# R7FA6T1 register map
Vendor: Renesas; Series: RA6; File version: 1.2
CPU: CM4 r0p1, little endian, MPU, FPU, VTOR, 4 interrupt priority bits
Registers are 8-bit, read-write, reset 0x0 unless marked. A register's access mark holds for its fields unless they carry their own. Offsets are from the block's base; [hi:lo] are bit positions; 'fields as' and 'values as' point back to an identical list.

## MSTP — Module Stop Control B,C,D
Base 0x40047000
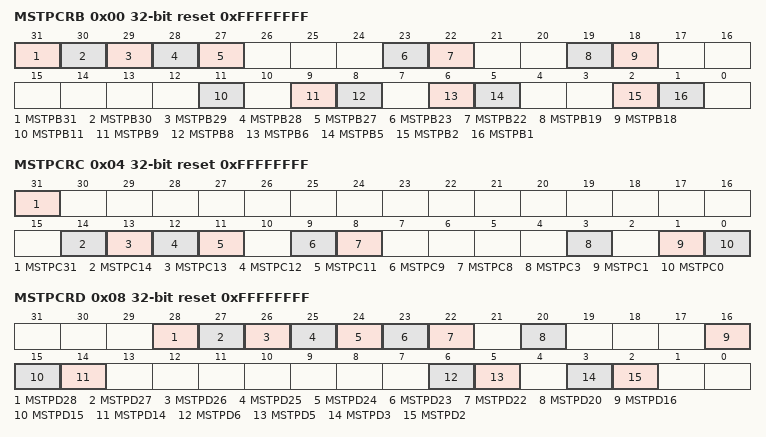
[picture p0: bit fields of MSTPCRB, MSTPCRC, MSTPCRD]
0x00 MSTPCRB 32-bit reset 0xFFFFFFFF — Module Stop Control Register B
  [all] fields
    0=Cancel the module-stop state; 1=Enter the module-stop state
  [31] MSTPB31 — Serial Communication Interface 0 Module Stop
  [30] MSTPB30 — Serial Communication Interface 1 Module Stop
  [29] MSTPB29 — Serial Communication Interface 2 Module Stop
  [28] MSTPB28 — Serial Communication Interface 3 Module Stop
  [27] MSTPB27 — Serial Communication Interface 4 Module Stop
  [23] MSTPB23 — Serial Communication Interface 8 Module Stop
  [22] MSTPB22 — Serial Communication Interface 9 Module Stop
  [19] MSTPB19 — Serial Peripheral Interface 0 Module Stop
  [18] MSTPB18 — Serial Peripheral Interface Module Stop
  [11] MSTPB11 — Universal Serial Bus 2.0 FS Interface Module Stop
  [9] MSTPB9 — I2C Bus Interface 0 Module Stop
  [8] MSTPB8 — I2C Bus Interface 1 Module Stop
  [6] MSTPB6 — Queued Serial Peripheral Interface Module Stop
  [5] MSTPB5 — IrDA Module Stop
  [2] MSTPB2 — Controller Area Network 0 Module Stop
  [1] MSTPB1 — Controller Area Network 1 Module Stop
0x04 MSTPCRC 32-bit reset 0xFFFFFFFF — Module Stop Control Register C
  [all] fields
    values as the fields of MSTPCRB
  [31] MSTPC31 — SCE7 Module Stop
  [14] MSTPC14 — Event Link Controller Module Stop
  [13] MSTPC13 — Data Operation Circuit Module Stop
  [12] MSTPC12 — Secure Digital Host IF/MultiMediaCard 0 Module Stop
  [11] MSTPC11 — Secure Digital Host IF/MultiMediaCard 1 Module Stop
  [9] MSTPC9 — Sampling Rate Converter Module Stop
  [8] MSTPC8 — Serial Sound Interface Enhanced (channel 0) Module Stop
  [3] MSTPC3 — Capacitive Touch Sensing Unit Module Stop
  [1] MSTPC1 — Cyclic Redundancy Check Calculator Module Stop
  [0] MSTPC0 — Clock Frequency Accuracy Measurement Circuit Module Stop
0x08 MSTPCRD 32-bit reset 0xFFFFFFFF — Module Stop Control Register D
  [all] fields
    values as the fields of MSTPCRB
  [28] MSTPD28 — High-Speed Analog Comparator 0 Module Stop
  [27] MSTPD27 — High-Speed Analog Comparator 1 Module Stop
  [26] MSTPD26 — High-Speed Analog Comparator 2 Module Stop
  [25] MSTPD25 — High-Speed Analog Comparator 3 Module Stop
  [24] MSTPD24 — High-Speed Analog Comparator 4 Module Stop
  [23] MSTPD23 — High-Speed Analog Comparator 5 Module Stop
  [22] MSTPD22 — Temperature Sensor Module Stop
  [20] MSTPD20 — 12-Bit D/A Converter Module Stop
  [16] MSTPD16 — 12-Bit A/D Converter 0 Module Stop
  [15] MSTPD15 — 12-Bit A/D Converter 1 Module Stop
  [14] MSTPD14 — Port Output Enable for GPT Module Stop
  [6] MSTPD6 — General PWM Timer 32_8 to 32_12 Module Stop
  [5] MSTPD5 — General PWM Timer 32EH0 to 32EH3 and 32E4 to 32E7 and PWM Delay Generation Circuit Module Stop
  [3] MSTPD3 — AGT0 Module Stop Note: AGT0 is in the module stop state when the count source is either of PCLKB, PCLKB/2 or PCLKB/8. In case the count source is sub-clock or LOCO, this bit should be set to 1 except when accessing the registers of AGT0.
  [2] MSTPD2 — AGT1 Module Stop Note: AGT1 is in the module stop state when the count source is either of PCLKB, PCLKB/2 or PCLKB/8. In case the count source is sub-clock or LOCO, this bit should be set to 1 except when accessing the registers of AGT1.

## DOC — Data Operation Circuit
Base 0x40054100
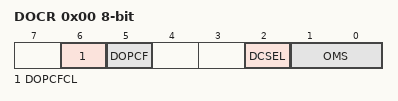
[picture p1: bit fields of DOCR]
0x00 DOCR — DOC Control Register
  [6] DOPCFCL — DOPCF Clear
    0=Maintains the DOPCF flag state; 1=Clears the DOPCF flag
  [5] DOPCF ro — Data Operation Circuit FlagIndicates the result of an operation.
  [2] DCSEL — Detection Condition Select
    0=DOPCF is set when data mismatch is detected; 1=DOPCF is set when data match is detected
  [1:0] OMS — Operating Mode Select
    0=Data comparison mode; 1=Data addition mode; 2=Data subtraction mode; 3=Setting prohibited
0x02 DODIR 16-bit — DOC Data Input Register
  [15:0] DODIR — 16-bit read-write register in which 16-bit data for use in the operations are stored.
0x04 DODSR 16-bit — DOC Data Setting Register
  [15:0] DODSR — This register stores 16-bit data for use as a reference in data comparison mode. This register also stores the results of operations in data addition and data subtraction modes.
